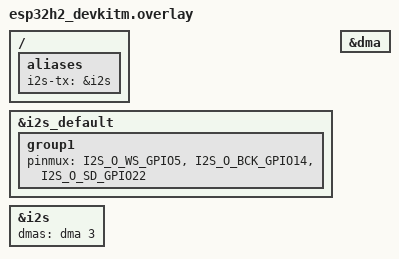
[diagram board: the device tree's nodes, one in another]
/*
 * Copyright (c) 2025 Espressif Systems (Shanghai) Co., Ltd.
 *
 * SPDX-License-Identifier: Apache-2.0
 */

/ {
	aliases {
		i2s-tx = &i2s;
	};
};

&i2s_default {
	group1 {
		pinmux = <I2S_O_WS_GPIO5>,
			 <I2S_O_BCK_GPIO14>,
			 <I2S_O_SD_GPIO22>;
	};
};

&i2s {

	dmas = <&dma 3>;
	dma-names = "tx";
	status = "okay";
};

&dma {
	status = "okay";
};
